AUTOSAR XML (schema 4-2-2)
package /STELLANTIS/EPT/ASWCs
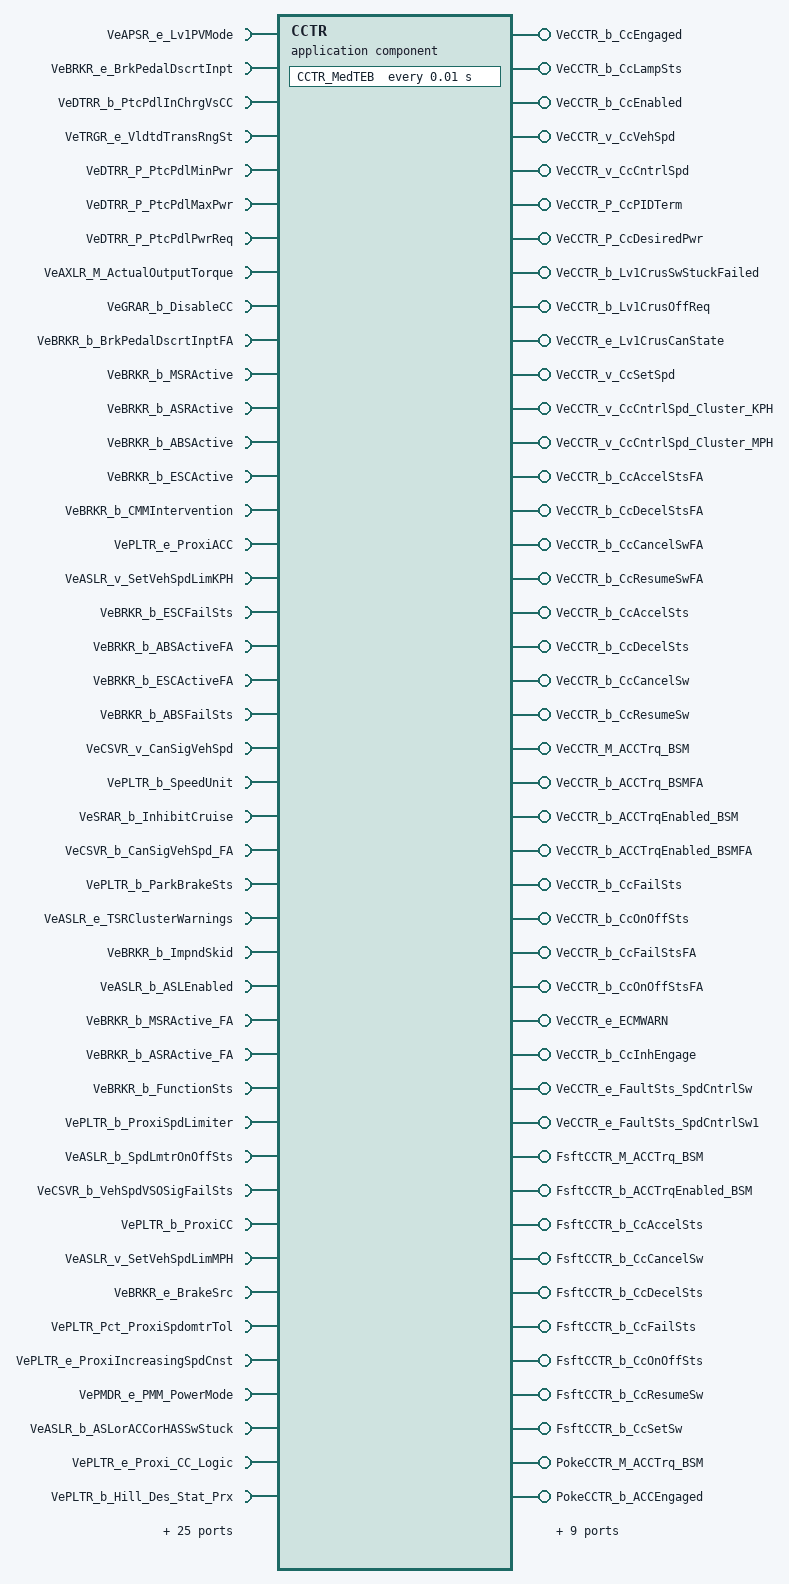
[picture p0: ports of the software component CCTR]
  application sw component type CCTR
    67 x require port:
      VeAPSR_e_Lv1PVMode: variation-point={short-label=vpVeAPSR_e_Lv1PVMode, sw-syscond=1}, nonqueued-receiver-com-spec{data-element=Value, init-value=CeAPSR_e_LV1PVMode_NotValid}, required-interface=VeAPSR_e_Lv1PVMode
      VeBRKR_e_BrkPedalDscrtInpt: variation-point={short-label=vpVeBRKR_e_BrkPedalDscrtInpt, sw-syscond=1}, nonqueued-receiver-com-spec{data-element=Value, init-value=CeBRKR_e_BrkNotApplied}, required-interface=VeBRKR_e_BrkPedalDscrtInpt
      VeDTRR_b_PtcPdlInChrgVsCC: variation-point={short-label=vpVeDTRR_b_PtcPdlInChrgVsCC, sw-syscond=1}, nonqueued-receiver-com-spec{data-element=Value, init-value=0}, required-interface=VeDTRR_b_PtcPdlInChrgVsCC
      VeTRGR_e_VldtdTransRngSt: variation-point={short-label=vpVeTRGR_e_VldtdTransRngSt, sw-syscond=1}, nonqueued-receiver-com-spec{data-element=Value, init-value=CeTRGR_e_NoSelectionAvailable}, required-interface=VeTRGR_e_VldtdTransRngSt
      VeDTRR_P_PtcPdlMinPwr: variation-point={short-label=vpVeDTRR_P_PtcPdlMinPwr, sw-syscond=1}, nonqueued-receiver-com-spec{data-element=Value, init-value=0}, required-interface=VeDTRR_P_PtcPdlMinPwr
      VeDTRR_P_PtcPdlMaxPwr: variation-point={short-label=vpVeDTRR_P_PtcPdlMaxPwr, sw-syscond=1}, nonqueued-receiver-com-spec{data-element=Value, init-value=0}, required-interface=VeDTRR_P_PtcPdlMaxPwr
      VeDTRR_P_PtcPdlPwrReq: variation-point={short-label=vpVeDTRR_P_PtcPdlPwrReq, sw-syscond=1}, nonqueued-receiver-com-spec{data-element=Value, init-value=0}, required-interface=VeDTRR_P_PtcPdlPwrReq
      VeAXLR_M_ActualOutputTorque: variation-point={short-label=vpVeAXLR_M_ActualOutputTorque, sw-syscond=1}, nonqueued-receiver-com-spec{data-element=Value, init-value=0}, required-interface=VeAXLR_M_ActualOutputTorque
      VeGRAR_b_DisableCC: variation-point={short-label=vpVeGRAR_b_DisableCC, sw-syscond=1}, nonqueued-receiver-com-spec{data-element=Value, init-value=0}, required-interface=VeGRAR_b_DisableCC
      VeBRKR_b_BrkPedalDscrtInptFA: variation-point={short-label=vpVeBRKR_b_BrkPedalDscrtInptFA, sw-syscond=1}, nonqueued-receiver-com-spec{data-element=Value, init-value=0}, required-interface=VeBRKR_b_BrkPedalDscrtInptFA
      VeBRKR_b_MSRActive: variation-point={short-label=vpVeBRKR_b_MSRActive, sw-syscond=1}, nonqueued-receiver-com-spec{data-element=Value, init-value=0}, required-interface=VeBRKR_b_MSRActive
      VeBRKR_b_ASRActive: variation-point={short-label=vpVeBRKR_b_ASRActive, sw-syscond=1}, nonqueued-receiver-com-spec{data-element=Value, init-value=0}, required-interface=VeBRKR_b_ASRActive
      VeBRKR_b_ABSActive: variation-point={short-label=vpVeBRKR_b_ABSActive, sw-syscond=1}, nonqueued-receiver-com-spec{data-element=Value, init-value=0}, required-interface=VeBRKR_b_ABSActive
      VeBRKR_b_ESCActive: variation-point={short-label=vpVeBRKR_b_ESCActive, sw-syscond=1}, nonqueued-receiver-com-spec{data-element=Value, init-value=0}, required-interface=VeBRKR_b_ESCActive
      VeBRKR_b_CMMIntervention: variation-point={short-label=vpVeBRKR_b_CMMIntervention, sw-syscond=1}, nonqueued-receiver-com-spec{data-element=Value, init-value=0}, required-interface=VeBRKR_b_CMMIntervention
      VePLTR_e_ProxiACC: variation-point={short-label=vpVePLTR_e_ProxiACC, sw-syscond=1}, nonqueued-receiver-com-spec{data-element=Value, init-value=CePLTR_e_ACC_Absent}, required-interface=VePLTR_e_ProxiACC
      VeASLR_v_SetVehSpdLimKPH: variation-point={short-label=vpVeASLR_v_SetVehSpdLimKPH, sw-syscond=1}, nonqueued-receiver-com-spec{data-element=Value, init-value=0}, required-interface=VeASLR_v_SetVehSpdLimKPH
      VeBRKR_b_ESCFailSts: variation-point={short-label=vpVeBRKR_b_ESCFailSts, sw-syscond=1}, nonqueued-receiver-com-spec{data-element=Value, init-value=0}, required-interface=VeBRKR_b_ESCFailSts
      VeBRKR_b_ABSActiveFA: variation-point={short-label=vpVeBRKR_b_ABSActiveFA, sw-syscond=1}, nonqueued-receiver-com-spec{data-element=Value, init-value=0}, required-interface=VeBRKR_b_ABSActiveFA
      VeBRKR_b_ESCActiveFA: variation-point={short-label=vpVeBRKR_b_ESCActiveFA, sw-syscond=1}, nonqueued-receiver-com-spec{data-element=Value, init-value=0}, required-interface=VeBRKR_b_ESCActiveFA
      VeBRKR_b_ABSFailSts: variation-point={short-label=vpVeBRKR_b_ABSFailSts, sw-syscond=1}, nonqueued-receiver-com-spec{data-element=Value, init-value=0}, required-interface=VeBRKR_b_ABSFailSts
      VeCSVR_v_CanSigVehSpd: variation-point={short-label=vpVeCSVR_v_CanSigVehSpd, sw-syscond=1}, nonqueued-receiver-com-spec{data-element=Value, init-value=0}, required-interface=VeCSVR_v_CanSigVehSpd
      VePLTR_b_SpeedUnit: variation-point={short-label=vpVePLTR_b_SpeedUnit, sw-syscond=1}, nonqueued-receiver-com-spec{data-element=Value, init-value=0}, required-interface=VePLTR_b_SpeedUnit
      VeSRAR_b_InhibitCruise: variation-point={short-label=vpVeSRAR_b_InhibitCruise, sw-syscond=1}, nonqueued-receiver-com-spec{data-element=Value, init-value=0}, required-interface=VeSRAR_b_InhibitCruise
      VeCSVR_b_CanSigVehSpd_FA: variation-point={short-label=vpVeCSVR_b_CanSigVehSpd_FA, sw-syscond=1}, nonqueued-receiver-com-spec{data-element=Value, init-value=0}, required-interface=VeCSVR_b_CanSigVehSpd_FA
      VePLTR_b_ParkBrakeSts: variation-point={short-label=vpVePLTR_b_ParkBrakeSts, sw-syscond=1}, nonqueued-receiver-com-spec{data-element=Value, init-value=0}, required-interface=VePLTR_b_ParkBrakeSts
      VeASLR_e_TSRClusterWarnings: variation-point={short-label=vpVeASLR_e_TSRClusterWarnings, sw-syscond=1}, nonqueued-receiver-com-spec{data-element=Value, init-value=0}, required-interface=VeASLR_e_TSRClusterWarnings
      VeBRKR_b_ImpndSkid: variation-point={short-label=vpVeBRKR_b_ImpndSkid, sw-syscond=1}, nonqueued-receiver-com-spec{data-element=Value, init-value=0}, required-interface=VeBRKR_b_ImpndSkid
      VeASLR_b_ASLEnabled: variation-point={short-label=vpVeASLR_b_ASLEnabled, sw-syscond=1}, nonqueued-receiver-com-spec{data-element=Value, init-value=0}, required-interface=VeASLR_b_ASLEnabled
      VeBRKR_b_MSRActive_FA: variation-point={short-label=vpVeBRKR_b_MSRActive_FA, sw-syscond=1}, nonqueued-receiver-com-spec{data-element=Value, init-value=0}, required-interface=VeBRKR_b_MSRActive_FA
      VeBRKR_b_ASRActive_FA: variation-point={short-label=vpVeBRKR_b_ASRActive_FA, sw-syscond=1}, nonqueued-receiver-com-spec{data-element=Value, init-value=0}, required-interface=VeBRKR_b_ASRActive_FA
      VeBRKR_b_FunctionSts: variation-point={short-label=vpVeBRKR_b_FunctionSts, sw-syscond=1}, nonqueued-receiver-com-spec{data-element=Value, init-value=0}, required-interface=VeBRKR_b_FunctionSts
      VePLTR_b_ProxiSpdLimiter: variation-point={short-label=vpVePLTR_b_ProxiSpdLimiter, sw-syscond=1}, nonqueued-receiver-com-spec{data-element=Value, init-value=0}, required-interface=VePLTR_b_ProxiSpdLimiter
      VeASLR_b_SpdLmtrOnOffSts: variation-point={short-label=vpVeASLR_b_SpdLmtrOnOffSts, sw-syscond=1}, nonqueued-receiver-com-spec{data-element=Value, init-value=0}, required-interface=VeASLR_b_SpdLmtrOnOffSts
      VeCSVR_b_VehSpdVSOSigFailSts: variation-point={short-label=vpVeCSVR_b_VehSpdVSOSigFailSts, sw-syscond=1}, nonqueued-receiver-com-spec{data-element=Value, init-value=0}, required-interface=VeCSVR_b_VehSpdVSOSigFailSts
      VePLTR_b_ProxiCC: variation-point={short-label=vpVePLTR_b_ProxiCC, sw-syscond=1}, nonqueued-receiver-com-spec{data-element=Value, init-value=0}, required-interface=VePLTR_b_ProxiCC
      VeASLR_v_SetVehSpdLimMPH: variation-point={short-label=vpVeASLR_v_SetVehSpdLimMPH, sw-syscond=1}, nonqueued-receiver-com-spec{data-element=Value, init-value=0}, required-interface=VeASLR_v_SetVehSpdLimMPH
      VeBRKR_e_BrakeSrc: variation-point={short-label=vpVeBRKR_e_BrakeSrc, sw-syscond=1}, nonqueued-receiver-com-spec{data-element=Value, init-value=CeBRKR_e_BrkPdlDscrtInpt}, required-interface=VeBRKR_e_BrakeSrc
      VePLTR_Pct_ProxiSpdomtrTol: variation-point={short-label=vpVePLTR_Pct_ProxiSpdomtrTol, sw-syscond=1}, nonqueued-receiver-com-spec{data-element=Value, init-value=0}, required-interface=VePLTR_Pct_ProxiSpdomtrTol
      VePLTR_e_ProxiIncreasingSpdCnst: variation-point={short-label=vpVePLTR_e_ProxiIncreasingSpdCnst, sw-syscond=1}, nonqueued-receiver-com-spec{data-element=Value, init-value=CePLTR_e_Increasing_0}, required-interface=VePLTR_e_ProxiIncreasingSpdCnst
      VePMDR_e_PMM_PowerMode: variation-point={short-label=vpVePMDR_e_PMM_PowerMode, sw-syscond=1}, nonqueued-receiver-com-spec{data-element=Value, init-value=CePMDR_e_PowerMode_Off}, required-interface=VePMDR_e_PMM_PowerMode
      VeASLR_b_ASLorACCorHASSwStuck: variation-point={short-label=vpVeASLR_b_ASLorACCorHASSwStuck, sw-syscond=1}, nonqueued-receiver-com-spec{data-element=Value, init-value=0}, required-interface=VeASLR_b_ASLorACCorHASSwStuck
      VePLTR_e_Proxi_CC_Logic: variation-point={short-label=vpVePLTR_e_Proxi_CC_Logic, sw-syscond=1}, nonqueued-receiver-com-spec{data-element=Value, init-value=CePLTR_e_Logic1}, required-interface=VePLTR_e_Proxi_CC_Logic
      VePLTR_b_Hill_Des_Stat_Prx: variation-point={short-label=vpVePLTR_b_Hill_Des_Stat_Prx, sw-syscond=1}, nonqueued-receiver-com-spec{data-element=Value, init-value=0}, required-interface=VePLTR_b_Hill_Des_Stat_Prx
      VeBRKR_e_ExtTcsReqOff: variation-point={short-label=vpVeBRKR_e_ExtTcsReqOff, sw-syscond=1}, nonqueued-receiver-com-spec{data-element=Value, init-value=CeBRKR_e_NoReq}, required-interface=VeBRKR_e_ExtTcsReqOff
      VeBRKR_e_ExtBrkReqOff: variation-point={short-label=vpVeBRKR_e_ExtBrkReqOff, sw-syscond=1}, nonqueued-receiver-com-spec{data-element=Value, init-value=CeBRKR_e_NoReq}, required-interface=VeBRKR_e_ExtBrkReqOff
      VeASLR_e_HDC_Status: variation-point={short-label=vpVeASLR_e_HDC_Status, sw-syscond=1}, nonqueued-receiver-com-spec{data-element=Value, init-value=CeASLR_e_HDC_UNAVL}, required-interface=VeASLR_e_HDC_Status
      VePLTR_e_EPBHoldSts: variation-point={short-label=vpVePLTR_e_EPBHoldSts, sw-syscond=1}, nonqueued-receiver-com-spec{data-element=Value, init-value=CePLTR_e_EPBHoldSts_REL}, required-interface=VePLTR_e_EPBHoldSts
      VeTMDR_e_TrrnMd: variation-point={short-label=vpVeTMDR_e_TrrnMd, sw-syscond=1}, nonqueued-receiver-com-spec{data-element=Value, init-value=CeTMDR_e_NotDefine}, required-interface=VeTMDR_e_TrrnMd
      VePLTR_b_EPBHoldStsFA: variation-point={short-label=vpVePLTR_b_EPBHoldStsFA, sw-syscond=1}, nonqueued-receiver-com-spec{data-element=Value, init-value=0}, required-interface=VePLTR_b_EPBHoldStsFA
      VeBRKR_b_ExtBrkReqOffFA: variation-point={short-label=vpVeBRKR_b_ExtBrkReqOffFA, sw-syscond=1}, nonqueued-receiver-com-spec{data-element=Value, init-value=0}, required-interface=VeBRKR_b_ExtBrkReqOffFA
      VeBRKR_b_BrkPdlFlt: variation-point={short-label=vpVeBRKR_b_BrkPdlFlt, sw-syscond=1}, nonqueued-receiver-com-spec{data-element=Value, init-value=0}, required-interface=VeBRKR_b_BrkPdlFlt
      VeBRKR_b_BrkPdlFltFA: variation-point={short-label=vpVeBRKR_b_BrkPdlFltFA, sw-syscond=1}, nonqueued-receiver-com-spec{data-element=Value, init-value=0}, required-interface=VeBRKR_b_BrkPdlFltFA
      VeBRKR_b_ESCFailStsFA: variation-point={short-label=vpVeBRKR_b_ESCFailStsFA, sw-syscond=1}, nonqueued-receiver-com-spec{data-element=Value, init-value=0}, required-interface=VeBRKR_b_ESCFailStsFA
      VeAPSR_b_Lv1PvBrkActive: variation-point={short-label=vpVeAPSR_b_Lv1PvBrkActive, sw-syscond=1}, nonqueued-receiver-com-spec{data-element=Value, init-value=0}, required-interface=VeAPSR_b_Lv1PvBrkActive
      VePLTR_v_HomSpdLim: variation-point={short-label=vpVePLTR_v_HomSpdLim, sw-syscond=1}, nonqueued-receiver-com-spec{data-element=Value, init-value=0}, required-interface=VePLTR_v_HomSpdLim
      VeASLR_v_STSpdLim: variation-point={short-label=vpVeASLR_v_STSpdLim, sw-syscond=1}, nonqueued-receiver-com-spec{data-element=Value, init-value=0}, required-interface=VeASLR_v_STSpdLim
      VeASLR_b_STSpdLimEnabled: variation-point={short-label=vpVeASLR_b_STSpdLimEnabled, sw-syscond=1}, nonqueued-receiver-com-spec{data-element=Value, init-value=0}, required-interface=VeASLR_b_STSpdLimEnabled
      VeASLR_b_HomSpdLimEnabled: variation-point={short-label=vpVeASLR_b_HomSpdLimEnabled, sw-syscond=1}, nonqueued-receiver-com-spec{data-element=Value, init-value=0}, required-interface=VeASLR_b_HomSpdLimEnabled
      VePLTR_b_HDCEnabledCAN: variation-point={short-label=vpVePLTR_b_HDCEnabledCAN, sw-syscond=1}, nonqueued-receiver-com-spec{data-element=Value, init-value=0}, required-interface=VePLTR_b_HDCEnabledCAN
      VePLTR_b_HDCEnabledCAN_FA: variation-point={short-label=vpVePLTR_b_HDCEnabledCAN_FA, sw-syscond=1}, nonqueued-receiver-com-spec{data-element=Value, init-value=0}, required-interface=VePLTR_b_HDCEnabledCAN_FA
      VeDFIR_b_DsblDiagFailSafe: variation-point={short-label=vpVeDFIR_b_DsblDiagFailSafe, sw-syscond=1}, nonqueued-receiver-com-spec{data-element=Value, init-value=0}, required-interface=VeDFIR_b_DsblDiagFailSafe
      VeDFIR_b_PostCodeClrDiagDsbl: variation-point={short-label=vpVeDFIR_b_PostCodeClrDiagDsbl, sw-syscond=1}, nonqueued-receiver-com-spec{data-element=Value, init-value=0}, required-interface=VeDFIR_b_PostCodeClrDiagDsbl
      VeDMAB_y_StatusByte_SpdCntrlSw: variation-point={short-label=vpVeDMAB_y_StatusByte_SpdCntrlSw, sw-syscond=1}, nonqueued-receiver-com-spec{data-element=Value, init-value=0}, required-interface=VeDMAB_y_StatusByte_SpdCntrlSw
      VePLTR_e_BSM_AxleTrq_Enbld: variation-point={short-label=vpVePLTR_e_BSM_AxleTrq_Enbld, sw-syscond=1}, nonqueued-receiver-com-spec{data-element=Value, init-value=CePLTR_e_No_Req}, required-interface=VePLTR_e_BSM_AxleTrq_Enbld
      VeDFIR_b_IsDiagGlobalConditionsValid: variation-point={short-label=vpVeDFIR_b_IsDiagGlobalConditionsValid, sw-syscond=1}, nonqueued-receiver-com-spec{data-element=Value, init-value=0}, required-interface=VeDFIR_b_IsDiagGlobalConditionsValid
      VeDMAB_y_StatusByte_SpdCntrlSw1: variation-point={short-label=vpVeDMAB_y_StatusByte_SpdCntrlSw1, sw-syscond=1}, nonqueued-receiver-com-spec{data-element=Value, init-value=0}, required-interface=VeDMAB_y_StatusByte_SpdCntrlSw1
    52 x provide port:
      VeCCTR_b_CcEngaged: variation-point={short-label=vpVeCCTR_b_CcEngaged, sw-syscond=1}, nonqueued-sender-com-spec{data-element=Value, init-value=0}, provided-interface=VeCCTR_b_CcEngaged
      VeCCTR_b_CcLampSts: variation-point={short-label=vpVeCCTR_b_CcLampSts, sw-syscond=1}, nonqueued-sender-com-spec{data-element=Value, init-value=0}, provided-interface=VeCCTR_b_CcLampSts
      VeCCTR_b_CcEnabled: variation-point={short-label=vpVeCCTR_b_CcEnabled, sw-syscond=1}, nonqueued-sender-com-spec{data-element=Value, init-value=0}, provided-interface=VeCCTR_b_CcEnabled
      VeCCTR_v_CcVehSpd: variation-point={short-label=vpVeCCTR_v_CcVehSpd, sw-syscond=1}, nonqueued-sender-com-spec{data-element=Value, init-value=0}, provided-interface=VeCCTR_v_CcVehSpd
      VeCCTR_v_CcCntrlSpd: variation-point={short-label=vpVeCCTR_v_CcCntrlSpd, sw-syscond=1}, nonqueued-sender-com-spec{data-element=Value, init-value=0}, provided-interface=VeCCTR_v_CcCntrlSpd
      VeCCTR_P_CcPIDTerm: variation-point={short-label=vpVeCCTR_P_CcPIDTerm, sw-syscond=1}, nonqueued-sender-com-spec{data-element=Value, init-value=0}, provided-interface=VeCCTR_P_CcPIDTerm
      VeCCTR_P_CcDesiredPwr: variation-point={short-label=vpVeCCTR_P_CcDesiredPwr, sw-syscond=1}, nonqueued-sender-com-spec{data-element=Value, init-value=0}, provided-interface=VeCCTR_P_CcDesiredPwr
      VeCCTR_b_Lv1CrusSwStuckFailed: variation-point={short-label=vpVeCCTR_b_Lv1CrusSwStuckFailed, sw-syscond=1}, nonqueued-sender-com-spec{data-element=Value, init-value=0}, provided-interface=VeCCTR_b_Lv1CrusSwStuckFailed
      VeCCTR_b_Lv1CrusOffReq: variation-point={short-label=vpVeCCTR_b_Lv1CrusOffReq, sw-syscond=1}, nonqueued-sender-com-spec{data-element=Value, init-value=0}, provided-interface=VeCCTR_b_Lv1CrusOffReq
      VeCCTR_e_Lv1CrusCanState: variation-point={short-label=vpVeCCTR_e_Lv1CrusCanState, sw-syscond=1}, nonqueued-sender-com-spec{data-element=Value, init-value=0}, provided-interface=VeCCTR_e_Lv1CrusCanState
      VeCCTR_v_CcSetSpd: variation-point={short-label=vpVeCCTR_v_CcSetSpd, sw-syscond=1}, nonqueued-sender-com-spec{data-element=Value, init-value=0}, provided-interface=VeCCTR_v_CcSetSpd
      VeCCTR_v_CcCntrlSpd_Cluster_KPH: variation-point={short-label=vpVeCCTR_v_CcCntrlSpd_Cluster_KPH, sw-syscond=1}, nonqueued-sender-com-spec{data-element=Value, init-value=0}, provided-interface=VeCCTR_v_CcCntrlSpd_Cluster_KPH
      VeCCTR_v_CcCntrlSpd_Cluster_MPH: variation-point={short-label=vpVeCCTR_v_CcCntrlSpd_Cluster_MPH, sw-syscond=1}, nonqueued-sender-com-spec{data-element=Value, init-value=0}, provided-interface=VeCCTR_v_CcCntrlSpd_Cluster_MPH
      VeCCTR_b_CcAccelStsFA: nonqueued-sender-com-spec{data-element=Value, init-value=0}, provided-interface=VeCCTR_b_CcAccelStsFA
      VeCCTR_b_CcDecelStsFA: nonqueued-sender-com-spec{data-element=Value, init-value=0}, provided-interface=VeCCTR_b_CcDecelStsFA
      VeCCTR_b_CcCancelSwFA: nonqueued-sender-com-spec{data-element=Value, init-value=0}, provided-interface=VeCCTR_b_CcCancelSwFA
      VeCCTR_b_CcResumeSwFA: nonqueued-sender-com-spec{data-element=Value, init-value=0}, provided-interface=VeCCTR_b_CcResumeSwFA
      VeCCTR_b_CcAccelSts: variation-point={short-label=vpVeCCTR_b_CcAccelSts, sw-syscond=1}, nonqueued-sender-com-spec{data-element=Value, init-value=0}, provided-interface=VeCCTR_b_CcAccelSts
      VeCCTR_b_CcDecelSts: variation-point={short-label=vpVeCCTR_b_CcDecelSts, sw-syscond=1}, nonqueued-sender-com-spec{data-element=Value, init-value=0}, provided-interface=VeCCTR_b_CcDecelSts
      VeCCTR_b_CcCancelSw: variation-point={short-label=vpVeCCTR_b_CcCancelSw, sw-syscond=1}, nonqueued-sender-com-spec{data-element=Value, init-value=0}, provided-interface=VeCCTR_b_CcCancelSw
      VeCCTR_b_CcResumeSw: variation-point={short-label=vpVeCCTR_b_CcResumeSw, sw-syscond=1}, nonqueued-sender-com-spec{data-element=Value, init-value=0}, provided-interface=VeCCTR_b_CcResumeSw
      VeCCTR_M_ACCTrq_BSM: nonqueued-sender-com-spec{data-element=Value, init-value=0}, provided-interface=VeCCTR_M_ACCTrq_BSM
      VeCCTR_b_ACCTrq_BSMFA: nonqueued-sender-com-spec{data-element=Value, init-value=0}, provided-interface=VeCCTR_b_ACCTrq_BSMFA
      VeCCTR_b_ACCTrqEnabled_BSM: variation-point={short-label=vpVeCCTR_b_ACCTrqEnabled_BSM, sw-syscond=1}, nonqueued-sender-com-spec{data-element=Value, init-value=0}, provided-interface=VeCCTR_b_ACCTrqEnabled_BSM
      VeCCTR_b_ACCTrqEnabled_BSMFA: variation-point={short-label=vpVeCCTR_b_ACCTrqEnabled_BSMFA, sw-syscond=1}, nonqueued-sender-com-spec{data-element=Value, init-value=0}, provided-interface=VeCCTR_b_ACCTrqEnabled_BSMFA
      VeCCTR_b_CcFailSts: nonqueued-sender-com-spec{data-element=Value, init-value=0}, provided-interface=VeCCTR_b_CcFailSts
      VeCCTR_b_CcOnOffSts: nonqueued-sender-com-spec{data-element=Value, init-value=0}, provided-interface=VeCCTR_b_CcOnOffSts
      VeCCTR_b_CcFailStsFA: nonqueued-sender-com-spec{data-element=Value, init-value=0}, provided-interface=VeCCTR_b_CcFailStsFA
      VeCCTR_b_CcOnOffStsFA: nonqueued-sender-com-spec{data-element=Value, init-value=0}, provided-interface=VeCCTR_b_CcOnOffStsFA
      VeCCTR_e_ECMWARN: variation-point={short-label=vpVeCCTR_e_ECMWARN, sw-syscond=1}, nonqueued-sender-com-spec{data-element=Value, init-value=0}, provided-interface=VeCCTR_e_ECMWARN
      VeCCTR_b_CcInhEngage: variation-point={short-label=vpVeCCTR_b_CcInhEngage, sw-syscond=1}, nonqueued-sender-com-spec{data-element=Value, init-value=0}, provided-interface=VeCCTR_b_CcInhEngage
      VeCCTR_e_FaultSts_SpdCntrlSw: nonqueued-sender-com-spec{data-element=Value, init-value=CeDFIB_e_Init}, provided-interface=VeCCTR_e_FaultSts_SpdCntrlSw
      VeCCTR_e_FaultSts_SpdCntrlSw1: nonqueued-sender-com-spec{data-element=Value, init-value=CeDFIB_e_Init}, provided-interface=VeCCTR_e_FaultSts_SpdCntrlSw1
      FsftCCTR_M_ACCTrq_BSM: server-com-spec=FsftCCTR_M_ACCTrq_BSM, provided-interface=FsftCCTR_M_ACCTrq_BSM
      FsftCCTR_b_ACCTrqEnabled_BSM: server-com-spec=FsftCCTR_b_ACCTrqEnabled_BSM, provided-interface=FsftCCTR_b_ACCTrqEnabled_BSM
      FsftCCTR_b_CcAccelSts: server-com-spec=FsftCCTR_b_CcAccelSts, provided-interface=FsftCCTR_b_CcAccelSts
      FsftCCTR_b_CcCancelSw: server-com-spec=FsftCCTR_b_CcCancelSw, provided-interface=FsftCCTR_b_CcCancelSw
      FsftCCTR_b_CcDecelSts: server-com-spec=FsftCCTR_b_CcDecelSts, provided-interface=FsftCCTR_b_CcDecelSts
      FsftCCTR_b_CcFailSts: server-com-spec=FsftCCTR_b_CcFailSts, provided-interface=FsftCCTR_b_CcFailSts
      FsftCCTR_b_CcOnOffSts: server-com-spec=FsftCCTR_b_CcOnOffSts, provided-interface=FsftCCTR_b_CcOnOffSts
      FsftCCTR_b_CcResumeSw: server-com-spec=FsftCCTR_b_CcResumeSw, provided-interface=FsftCCTR_b_CcResumeSw
      FsftCCTR_b_CcSetSw: server-com-spec=FsftCCTR_b_CcSetSw, provided-interface=FsftCCTR_b_CcSetSw
      PokeCCTR_M_ACCTrq_BSM: server-com-spec{operation=PokeCCTR_M_ACCTrq_BSM, queue-length=1}, provided-interface=PokeCCTR_M_ACCTrq_BSM
      PokeCCTR_b_ACCEngaged: server-com-spec{operation=PokeCCTR_b_ACCEngaged, queue-length=1}, provided-interface=PokeCCTR_b_ACCEngaged
      PokeCCTR_b_ACCTrqEnabled_BSM: server-com-spec{operation=PokeCCTR_b_ACCTrqEnabled_BSM, queue-length=1}, provided-interface=PokeCCTR_b_ACCTrqEnabled_BSM
      PokeCCTR_b_CcAccelSts: server-com-spec{operation=PokeCCTR_b_CcAccelSts, queue-length=1}, provided-interface=PokeCCTR_b_CcAccelSts
      PokeCCTR_b_CcCancelSw: server-com-spec{operation=PokeCCTR_b_CcCancelSw, queue-length=1}, provided-interface=PokeCCTR_b_CcCancelSw
      PokeCCTR_b_CcDecelSts: server-com-spec{operation=PokeCCTR_b_CcDecelSts, queue-length=1}, provided-interface=PokeCCTR_b_CcDecelSts
      PokeCCTR_b_CcFailSts: server-com-spec{operation=PokeCCTR_b_CcFailSts, queue-length=1}, provided-interface=PokeCCTR_b_CcFailSts
      PokeCCTR_b_CcOnOffSts: server-com-spec{operation=PokeCCTR_b_CcOnOffSts, queue-length=1}, provided-interface=PokeCCTR_b_CcOnOffSts
      PokeCCTR_b_CcResumeSw: server-com-spec{operation=PokeCCTR_b_CcResumeSw, queue-length=1}, provided-interface=PokeCCTR_b_CcResumeSw
      PokeCCTR_b_CcSetSw: server-com-spec{operation=PokeCCTR_b_CcSetSw, queue-length=1}, provided-interface=PokeCCTR_b_CcSetSw
    require port NeCCTR_Cnt_SpdCntrlSw1_MFOP_Rx: nv-require-com-spec{init-value=0, variable=NeCCTR_Cnt_SpdCntrlSw1_MFOP}, required-interface=NeCCTR_Cnt_SpdCntrlSw1_MFOP
    provide port NeCCTR_Cnt_SpdCntrlSw1_MFOP: nv-provide-com-spec{ram-block-init-value=0, variable=NeCCTR_Cnt_SpdCntrlSw1_MFOP}, provided-interface=NeCCTR_Cnt_SpdCntrlSw1_MFOP
    require port KeASLR_b_ASLInstantActivationEnable: parameter-require-com-spec{init-value=KeASLR_b_ASLInstantActivationEnable_KeASLR_b_ASLInstantActivationEnable:1, parameter=KeASLR_b_ASLInstantActivationEnable}, required-interface=KeASLR_b_ASLInstantActivationEnable
    behavior IB_CCTR: data-type-mapping=msADTtoIDTMapping, handle-termination-and-restart=NO-SUPPORT
      timing event Event_MedTEB: start-on-event=CCTR_MedTEB, period=0.01
      19 x operation invoked event:
        Event_FsftCCTR_M_ACCTrq_BSM: start-on-event=FsftCCTR_M_ACCTrq_BSM, operation=FsftCCTR_M_ACCTrq_BSM.FsftCCTR_M_ACCTrq_BSM
        Event_FsftCCTR_b_ACCTrqEnabled_BSM: start-on-event=FsftCCTR_b_ACCTrqEnabled_BSM, operation=FsftCCTR_b_ACCTrqEnabled_BSM.FsftCCTR_b_ACCTrqEnabled_BSM
        Event_FsftCCTR_b_CcAccelSts: start-on-event=FsftCCTR_b_CcAccelSts, operation=FsftCCTR_b_CcAccelSts.FsftCCTR_b_CcAccelSts
        Event_FsftCCTR_b_CcCancelSw: start-on-event=FsftCCTR_b_CcCancelSw, operation=FsftCCTR_b_CcCancelSw.FsftCCTR_b_CcCancelSw
        Event_FsftCCTR_b_CcDecelSts: start-on-event=FsftCCTR_b_CcDecelSts, operation=FsftCCTR_b_CcDecelSts.FsftCCTR_b_CcDecelSts
        Event_FsftCCTR_b_CcFailSts: start-on-event=FsftCCTR_b_CcFailSts, operation=FsftCCTR_b_CcFailSts.FsftCCTR_b_CcFailSts
        Event_FsftCCTR_b_CcOnOffSts: start-on-event=FsftCCTR_b_CcOnOffSts, operation=FsftCCTR_b_CcOnOffSts.FsftCCTR_b_CcOnOffSts
        Event_FsftCCTR_b_CcResumeSw: start-on-event=FsftCCTR_b_CcResumeSw, operation=FsftCCTR_b_CcResumeSw.FsftCCTR_b_CcResumeSw
        Event_FsftCCTR_b_CcSetSw: start-on-event=FsftCCTR_b_CcSetSw, operation=FsftCCTR_b_CcSetSw.FsftCCTR_b_CcSetSw
        Event_PokeCCTR_M_ACCTrq_BSM: start-on-event=PokeCCTR_M_ACCTrq_BSM, operation=PokeCCTR_M_ACCTrq_BSM.PokeCCTR_M_ACCTrq_BSM
        Event_PokeCCTR_b_ACCEngaged: start-on-event=PokeCCTR_b_ACCEngaged, operation=PokeCCTR_b_ACCEngaged.PokeCCTR_b_ACCEngaged
        Event_PokeCCTR_b_ACCTrqEnabled_BSM: start-on-event=PokeCCTR_b_ACCTrqEnabled_BSM, operation=PokeCCTR_b_ACCTrqEnabled_BSM.PokeCCTR_b_ACCTrqEnabled_BSM
        Event_PokeCCTR_b_CcAccelSts: start-on-event=PokeCCTR_b_CcAccelSts, operation=PokeCCTR_b_CcAccelSts.PokeCCTR_b_CcAccelSts
        Event_PokeCCTR_b_CcCancelSw: start-on-event=PokeCCTR_b_CcCancelSw, operation=PokeCCTR_b_CcCancelSw.PokeCCTR_b_CcCancelSw
        Event_PokeCCTR_b_CcDecelSts: start-on-event=PokeCCTR_b_CcDecelSts, operation=PokeCCTR_b_CcDecelSts.PokeCCTR_b_CcDecelSts
        Event_PokeCCTR_b_CcFailSts: start-on-event=PokeCCTR_b_CcFailSts, operation=PokeCCTR_b_CcFailSts.PokeCCTR_b_CcFailSts
        Event_PokeCCTR_b_CcOnOffSts: start-on-event=PokeCCTR_b_CcOnOffSts, operation=PokeCCTR_b_CcOnOffSts.PokeCCTR_b_CcOnOffSts
        Event_PokeCCTR_b_CcResumeSw: start-on-event=PokeCCTR_b_CcResumeSw, operation=PokeCCTR_b_CcResumeSw.PokeCCTR_b_CcResumeSw
        Event_PokeCCTR_b_CcSetSw: start-on-event=PokeCCTR_b_CcSetSw, operation=PokeCCTR_b_CcSetSw.PokeCCTR_b_CcSetSw
      init event Event_CCTR_ac_Init: start-on-event=CCTR_ac_Init
      init event Event_PwrOn: start-on-event=CCTR_PwrOn
      init event Event_PwrOff: start-on-event=CCTR_PwrOff
      explicit-inter-runnable-variables:
        16 x data, all with category=VALUE, sw-calibration-access=READ-ONLY, type=Boolean, init-value=0:
          CC_Accel_Sts_write_IRV: variation-point={short-label=vpCC_Accel_Sts_write_IRV, sw-syscond=1}
          CC_CoastDecelSts_write_IRV: variation-point={short-label=vpCC_CoastDecelSts_write_IRV, sw-syscond=1}
          CC_Cancel_Swtch_write_IRV: variation-point={short-label=vpCC_Cancel_Swtch_write_IRV, sw-syscond=1}
          CC_ResumeSwtch_write_IRV: variation-point={short-label=vpCC_ResumeSwtch_write_IRV, sw-syscond=1}
          CC_OnOff_Sts_write_IRV
          CC_SetSwtch_write_IRV: variation-point={short-label=vpCC_SetSwtch_write_IRV, sw-syscond=1}
          CC_AccelStsFA_write_IRV
          CC_CoastDecelStsFA_write_IRV
          CC_CancelSwtchFA_write_IRV
          CC_ResumeSwtchFA_write_IRV
          CC_FailSts_write_IRV
          CC_OnOffStsFA_write_IRV
          CC_SetSwtchFA_write_IRV
          CC_FailStsFA_write_IRV
          ACC_TrqEnabled_BSM_IRV
          ACC_TrqEnabled_BSMFA_IRV
      23 x runnable:
        CCTR_ac_Init
          data-send-points:
            access OUT_VeCCTR_e_FaultSts_SpdCntrlSw_Value: accessed-variable=VeCCTR_e_FaultSts_SpdCntrlSw.Value
            access OUT_VeCCTR_e_FaultSts_SpdCntrlSw1_Value: accessed-variable=VeCCTR_e_FaultSts_SpdCntrlSw1.Value
        CCTR_PwrOn
          data-receive-point-by-arguments:
            access IN_NeCCTR_Cnt_SpdCntrlSw1_MFOP_Rx_NeCCTR_Cnt_SpdCntrlSw1_MFOP: accessed-variable=NeCCTR_Cnt_SpdCntrlSw1_MFOP_Rx.NeCCTR_Cnt_SpdCntrlSw1_MFOP
          data-send-points:
            33 x access:
              OUT_VeCCTR_M_ACCTrq_BSM_Value: accessed-variable=VeCCTR_M_ACCTrq_BSM.Value
              OUT_VeCCTR_b_CcOnOffStsFA_Value: accessed-variable=VeCCTR_b_CcOnOffStsFA.Value
              OUT_VeCCTR_b_CcDecelStsFA_Value: accessed-variable=VeCCTR_b_CcDecelStsFA.Value
              OUT_VeCCTR_b_CcResumeSwFA_Value: accessed-variable=VeCCTR_b_CcResumeSwFA.Value
              OUT_VeCCTR_b_CcFailStsFA_Value: accessed-variable=VeCCTR_b_CcFailStsFA.Value
              OUT_VeCCTR_b_ACCTrq_BSMFA_Value: accessed-variable=VeCCTR_b_ACCTrq_BSMFA.Value
              OUT_VeCCTR_b_CcOnOffSts_Value: accessed-variable=VeCCTR_b_CcOnOffSts.Value
              OUT_VeCCTR_b_CcFailSts_Value: accessed-variable=VeCCTR_b_CcFailSts.Value
              OUT_VeCCTR_b_CcAccelStsFA_Value: accessed-variable=VeCCTR_b_CcAccelStsFA.Value
              OUT_VeCCTR_b_CcCancelSwFA_Value: accessed-variable=VeCCTR_b_CcCancelSwFA.Value
              OUT_VeCCTR_b_CcEngaged_Value: accessed-variable=VeCCTR_b_CcEngaged.Value, variation-point={short-label=vpOUT_VeCCTR_b_CcEngaged_Value, sw-syscond=1}
              OUT_VeCCTR_b_CcLampSts_Value: accessed-variable=VeCCTR_b_CcLampSts.Value, variation-point={short-label=vpOUT_VeCCTR_b_CcLampSts_Value, sw-syscond=1}
              OUT_VeCCTR_v_CcSetSpd_Value: accessed-variable=VeCCTR_v_CcSetSpd.Value, variation-point={short-label=vpOUT_VeCCTR_v_CcSetSpd_Value, sw-syscond=1}
              OUT_VeCCTR_v_CcCntrlSpd_Cluster_KPH_Value: accessed-variable=VeCCTR_v_CcCntrlSpd_Cluster_KPH.Value, variation-point={short-label=vpOUT_VeCCTR_v_CcCntrlSpd_Cluster_KPH_Value, sw-syscond=1}
              OUT_VeCCTR_v_CcCntrlSpd_Cluster_MPH_Value: accessed-variable=VeCCTR_v_CcCntrlSpd_Cluster_MPH.Value, variation-point={short-label=vpOUT_VeCCTR_v_CcCntrlSpd_Cluster_MPH_Value, sw-syscond=1}
              OUT_VeCCTR_b_CcAccelSts_Value: accessed-variable=VeCCTR_b_CcAccelSts.Value, variation-point={short-label=vpOUT_VeCCTR_b_CcAccelSts_Value, sw-syscond=1}
              OUT_VeCCTR_b_CcDecelSts_Value: accessed-variable=VeCCTR_b_CcDecelSts.Value, variation-point={short-label=vpOUT_VeCCTR_b_CcDecelSts_Value, sw-syscond=1}
              OUT_VeCCTR_b_CcCancelSw_Value: accessed-variable=VeCCTR_b_CcCancelSw.Value, variation-point={short-label=vpOUT_VeCCTR_b_CcCancelSw_Value, sw-syscond=1}
              OUT_VeCCTR_b_CcEnabled_Value: accessed-variable=VeCCTR_b_CcEnabled.Value, variation-point={short-label=vpOUT_VeCCTR_b_CcEnabled_Value, sw-syscond=1}
              OUT_VeCCTR_b_CcResumeSw_Value: accessed-variable=VeCCTR_b_CcResumeSw.Value, variation-point={short-label=vpOUT_VeCCTR_b_CcResumeSw_Value, sw-syscond=1}
              OUT_VeCCTR_e_ECMWARN_Value: accessed-variable=VeCCTR_e_ECMWARN.Value, variation-point={short-label=vpOUT_VeCCTR_e_ECMWARN_Value, sw-syscond=1}
              OUT_VeCCTR_v_CcVehSpd_Value: accessed-variable=VeCCTR_v_CcVehSpd.Value, variation-point={short-label=vpOUT_VeCCTR_v_CcVehSpd_Value, sw-syscond=1}
              OUT_VeCCTR_b_CcInhEngage_Value: accessed-variable=VeCCTR_b_CcInhEngage.Value, variation-point={short-label=vpOUT_VeCCTR_b_CcInhEngage_Value, sw-syscond=1}
              OUT_VeCCTR_v_CcCntrlSpd_Value: accessed-variable=VeCCTR_v_CcCntrlSpd.Value, variation-point={short-label=vpOUT_VeCCTR_v_CcCntrlSpd_Value, sw-syscond=1}
              OUT_VeCCTR_P_CcPIDTerm_Value: accessed-variable=VeCCTR_P_CcPIDTerm.Value, variation-point={short-label=vpOUT_VeCCTR_P_CcPIDTerm_Value, sw-syscond=1}
              OUT_VeCCTR_P_CcDesiredPwr_Value: accessed-variable=VeCCTR_P_CcDesiredPwr.Value, variation-point={short-label=vpOUT_VeCCTR_P_CcDesiredPwr_Value, sw-syscond=1}
              OUT_VeCCTR_b_Lv1CrusSwStuckFailed_Value: accessed-variable=VeCCTR_b_Lv1CrusSwStuckFailed.Value, variation-point={short-label=vpOUT_VeCCTR_b_Lv1CrusSwStuckFailed_Value, sw-syscond=1}
              OUT_VeCCTR_b_Lv1CrusOffReq_Value: accessed-variable=VeCCTR_b_Lv1CrusOffReq.Value, variation-point={short-label=vpOUT_VeCCTR_b_Lv1CrusOffReq_Value, sw-syscond=1}
              OUT_VeCCTR_e_Lv1CrusCanState_Value: accessed-variable=VeCCTR_e_Lv1CrusCanState.Value, variation-point={short-label=vpOUT_VeCCTR_e_Lv1CrusCanState_Value, sw-syscond=1}
              OUT_VeCCTR_e_FaultSts_SpdCntrlSw_Value: accessed-variable=VeCCTR_e_FaultSts_SpdCntrlSw.Value
              OUT_VeCCTR_b_ACCTrqEnabled_BSM_Value: accessed-variable=VeCCTR_b_ACCTrqEnabled_BSM.Value, variation-point={short-label=vpOUT_VeCCTR_b_ACCTrqEnabled_BSM_Value, sw-syscond=1}
              OUT_VeCCTR_b_ACCTrqEnabled_BSMFA_Value: accessed-variable=VeCCTR_b_ACCTrqEnabled_BSMFA.Value, variation-point={short-label=vpOUT_VeCCTR_b_ACCTrqEnabled_BSMFA_Value, sw-syscond=1}
              OUT_VeCCTR_e_FaultSts_SpdCntrlSw1_Value: accessed-variable=VeCCTR_e_FaultSts_SpdCntrlSw1.Value
          written-local-variables:
            16 x access:
              WV_ACC_TrqEnabled_BSMFA_IRV: accessed-variable=ACC_TrqEnabled_BSMFA_IRV
              WV_ACC_TrqEnabled_BSM_IRV: accessed-variable=ACC_TrqEnabled_BSM_IRV
              WV_CC_AccelStsFA_write_IRV: accessed-variable=CC_AccelStsFA_write_IRV
              WV_CC_Accel_Sts_write_IRV: accessed-variable=CC_Accel_Sts_write_IRV, variation-point={short-label=vpWV_CC_Accel_Sts_write_IRV, sw-syscond=1}
              WV_CC_CancelSwtchFA_write_IRV: accessed-variable=CC_CancelSwtchFA_write_IRV
              WV_CC_Cancel_Swtch_write_IRV: accessed-variable=CC_Cancel_Swtch_write_IRV, variation-point={short-label=vpWV_CC_Cancel_Swtch_write_IRV, sw-syscond=1}
              WV_CC_CoastDecelStsFA_write_IRV: accessed-variable=CC_CoastDecelStsFA_write_IRV
              WV_CC_CoastDecelSts_write_IRV: accessed-variable=CC_CoastDecelSts_write_IRV, variation-point={short-label=vpWV_CC_CoastDecelSts_write_IRV, sw-syscond=1}
              WV_CC_FailStsFA_write_IRV: accessed-variable=CC_FailStsFA_write_IRV
              WV_CC_FailSts_write_IRV: accessed-variable=CC_FailSts_write_IRV
              WV_CC_OnOffStsFA_write_IRV: accessed-variable=CC_OnOffStsFA_write_IRV
              WV_CC_OnOff_Sts_write_IRV: accessed-variable=CC_OnOff_Sts_write_IRV
              WV_CC_ResumeSwtchFA_write_IRV: accessed-variable=CC_ResumeSwtchFA_write_IRV
              WV_CC_ResumeSwtch_write_IRV: accessed-variable=CC_ResumeSwtch_write_IRV, variation-point={short-label=vpWV_CC_ResumeSwtch_write_IRV, sw-syscond=1}
              WV_CC_SetSwtchFA_write_IRV: accessed-variable=CC_SetSwtchFA_write_IRV
              WV_CC_SetSwtch_write_IRV: accessed-variable=CC_SetSwtch_write_IRV, variation-point={short-label=vpWV_CC_SetSwtch_write_IRV, sw-syscond=1}
        CCTR_MedTEB: variation-point={short-label=vpCCTR_MedTEB, sw-syscond=1}
          data-receive-point-by-arguments:
            67 x access:
              IN_VeAPSR_b_Lv1PvBrkActive_Value: accessed-variable=VeAPSR_b_Lv1PvBrkActive.Value, variation-point={short-label=vpIN_VeAPSR_b_Lv1PvBrkActive_Value, sw-syscond=1}
              IN_VeAPSR_e_Lv1PVMode_Value: accessed-variable=VeAPSR_e_Lv1PVMode.Value, variation-point={short-label=vpIN_VeAPSR_e_Lv1PVMode_Value, sw-syscond=1}
              IN_VeASLR_b_ASLEnabled_Value: accessed-variable=VeASLR_b_ASLEnabled.Value, variation-point={short-label=vpIN_VeASLR_b_ASLEnabled_Value, sw-syscond=1}
              IN_VeASLR_b_ASLorACCorHASSwStuck_Value: accessed-variable=VeASLR_b_ASLorACCorHASSwStuck.Value, variation-point={short-label=vpIN_VeASLR_b_ASLorACCorHASSwStuck_Value, sw-syscond=1}
              IN_VeASLR_b_HomSpdLimEnabled_Value: accessed-variable=VeASLR_b_HomSpdLimEnabled.Value, variation-point={short-label=vpIN_VeASLR_b_HomSpdLimEnabled_Value, sw-syscond=1}
              IN_VeASLR_b_STSpdLimEnabled_Value: accessed-variable=VeASLR_b_STSpdLimEnabled.Value, variation-point={short-label=vpIN_VeASLR_b_STSpdLimEnabled_Value, sw-syscond=1}
              IN_VeASLR_b_SpdLmtrOnOffSts_Value: accessed-variable=VeASLR_b_SpdLmtrOnOffSts.Value, variation-point={short-label=vpIN_VeASLR_b_SpdLmtrOnOffSts_Value, sw-syscond=1}
              IN_VeASLR_e_HDC_Status_Value: accessed-variable=VeASLR_e_HDC_Status.Value, variation-point={short-label=vpIN_VeASLR_e_HDC_Status_Value, sw-syscond=1}
              IN_VeASLR_e_TSRClusterWarnings_Value: accessed-variable=VeASLR_e_TSRClusterWarnings.Value, variation-point={short-label=vpIN_VeASLR_e_TSRClusterWarnings_Value, sw-syscond=1}
              IN_VeASLR_v_STSpdLim_Value: accessed-variable=VeASLR_v_STSpdLim.Value, variation-point={short-label=vpIN_VeASLR_v_STSpdLim_Value, sw-syscond=1}
              IN_VeASLR_v_SetVehSpdLimKPH_Value: accessed-variable=VeASLR_v_SetVehSpdLimKPH.Value, variation-point={short-label=vpIN_VeASLR_v_SetVehSpdLimKPH_Value, sw-syscond=1}
              IN_VeASLR_v_SetVehSpdLimMPH_Value: accessed-variable=VeASLR_v_SetVehSpdLimMPH.Value, variation-point={short-label=vpIN_VeASLR_v_SetVehSpdLimMPH_Value, sw-syscond=1}
              IN_VeAXLR_M_ActualOutputTorque_Value: accessed-variable=VeAXLR_M_ActualOutputTorque.Value, variation-point={short-label=vpIN_VeAXLR_M_ActualOutputTorque_Value, sw-syscond=1}
              IN_VeBRKR_b_ABSActive_Value: accessed-variable=VeBRKR_b_ABSActive.Value, variation-point={short-label=vpIN_VeBRKR_b_ABSActive_Value, sw-syscond=1}
              IN_VeBRKR_b_ABSActiveFA_Value: accessed-variable=VeBRKR_b_ABSActiveFA.Value, variation-point={short-label=vpIN_VeBRKR_b_ABSActiveFA_Value, sw-syscond=1}
              IN_VeBRKR_b_ABSFailSts_Value: accessed-variable=VeBRKR_b_ABSFailSts.Value, variation-point={short-label=vpIN_VeBRKR_b_ABSFailSts_Value, sw-syscond=1}
              IN_VeBRKR_b_ASRActive_Value: accessed-variable=VeBRKR_b_ASRActive.Value, variation-point={short-label=vpIN_VeBRKR_b_ASRActive_Value, sw-syscond=1}
              IN_VeBRKR_b_ASRActive_FA_Value: accessed-variable=VeBRKR_b_ASRActive_FA.Value, variation-point={short-label=vpIN_VeBRKR_b_ASRActive_FA_Value, sw-syscond=1}
              IN_VeBRKR_b_BrkPdlFlt_Value: accessed-variable=VeBRKR_b_BrkPdlFlt.Value, variation-point={short-label=vpIN_VeBRKR_b_BrkPdlFlt_Value, sw-syscond=1}
              IN_VeBRKR_b_BrkPdlFltFA_Value: accessed-variable=VeBRKR_b_BrkPdlFltFA.Value, variation-point={short-label=vpIN_VeBRKR_b_BrkPdlFltFA_Value, sw-syscond=1}
              IN_VeBRKR_b_BrkPedalDscrtInptFA_Value: accessed-variable=VeBRKR_b_BrkPedalDscrtInptFA.Value, variation-point={short-label=vpIN_VeBRKR_b_BrkPedalDscrtInptFA_Value, sw-syscond=1}
              IN_VeBRKR_b_CMMIntervention_Value: accessed-variable=VeBRKR_b_CMMIntervention.Value, variation-point={short-label=vpIN_VeBRKR_b_CMMIntervention_Value, sw-syscond=1}
              IN_VeBRKR_b_ESCActive_Value: accessed-variable=VeBRKR_b_ESCActive.Value, variation-point={short-label=vpIN_VeBRKR_b_ESCActive_Value, sw-syscond=1}
              IN_VeBRKR_b_ESCActiveFA_Value: accessed-variable=VeBRKR_b_ESCActiveFA.Value, variation-point={short-label=vpIN_VeBRKR_b_ESCActiveFA_Value, sw-syscond=1}
              IN_VeBRKR_b_ESCFailSts_Value: accessed-variable=VeBRKR_b_ESCFailSts.Value, variation-point={short-label=vpIN_VeBRKR_b_ESCFailSts_Value, sw-syscond=1}
              IN_VeBRKR_b_ESCFailStsFA_Value: accessed-variable=VeBRKR_b_ESCFailStsFA.Value, variation-point={short-label=vpIN_VeBRKR_b_ESCFailStsFA_Value, sw-syscond=1}
              IN_VeBRKR_b_ExtBrkReqOffFA_Value: accessed-variable=VeBRKR_b_ExtBrkReqOffFA.Value, variation-point={short-label=vpIN_VeBRKR_b_ExtBrkReqOffFA_Value, sw-syscond=1}
              IN_VeBRKR_b_FunctionSts_Value: accessed-variable=VeBRKR_b_FunctionSts.Value, variation-point={short-label=vpIN_VeBRKR_b_FunctionSts_Value, sw-syscond=1}
              IN_VeBRKR_b_ImpndSkid_Value: accessed-variable=VeBRKR_b_ImpndSkid.Value, variation-point={short-label=vpIN_VeBRKR_b_ImpndSkid_Value, sw-syscond=1}
              IN_VeBRKR_b_MSRActive_Value: accessed-variable=VeBRKR_b_MSRActive.Value, variation-point={short-label=vpIN_VeBRKR_b_MSRActive_Value, sw-syscond=1}
              IN_VeBRKR_b_MSRActive_FA_Value: accessed-variable=VeBRKR_b_MSRActive_FA.Value, variation-point={short-label=vpIN_VeBRKR_b_MSRActive_FA_Value, sw-syscond=1}
              IN_VeBRKR_e_BrakeSrc_Value: accessed-variable=VeBRKR_e_BrakeSrc.Value, variation-point={short-label=vpIN_VeBRKR_e_BrakeSrc_Value, sw-syscond=1}
              IN_VeBRKR_e_BrkPedalDscrtInpt_Value: accessed-variable=VeBRKR_e_BrkPedalDscrtInpt.Value, variation-point={short-label=vpIN_VeBRKR_e_BrkPedalDscrtInpt_Value, sw-syscond=1}
              IN_VeBRKR_e_ExtBrkReqOff_Value: accessed-variable=VeBRKR_e_ExtBrkReqOff.Value, variation-point={short-label=vpIN_VeBRKR_e_ExtBrkReqOff_Value, sw-syscond=1}
              IN_VeBRKR_e_ExtTcsReqOff_Value: accessed-variable=VeBRKR_e_ExtTcsReqOff.Value, variation-point={short-label=vpIN_VeBRKR_e_ExtTcsReqOff_Value, sw-syscond=1}
              IN_VeCSVR_b_CanSigVehSpd_FA_Value: accessed-variable=VeCSVR_b_CanSigVehSpd_FA.Value, variation-point={short-label=vpIN_VeCSVR_b_CanSigVehSpd_FA_Value, sw-syscond=1}
              IN_VeCSVR_b_VehSpdVSOSigFailSts_Value: accessed-variable=VeCSVR_b_VehSpdVSOSigFailSts.Value, variation-point={short-label=vpIN_VeCSVR_b_VehSpdVSOSigFailSts_Value, sw-syscond=1}
              IN_VeCSVR_v_CanSigVehSpd_Value: accessed-variable=VeCSVR_v_CanSigVehSpd.Value, variation-point={short-label=vpIN_VeCSVR_v_CanSigVehSpd_Value, sw-syscond=1}
              IN_VeDFIR_b_DsblDiagFailSafe_Value: accessed-variable=VeDFIR_b_DsblDiagFailSafe.Value, variation-point={short-label=vpIN_VeDFIR_b_DsblDiagFailSafe_Value, sw-syscond=1}
              IN_VeDFIR_b_IsDiagGlobalConditionsValid_Value: accessed-variable=VeDFIR_b_IsDiagGlobalConditionsValid.Value, variation-point={short-label=vpIN_VeDFIR_b_IsDiagGlobalConditionsValid_Value, sw-syscond=1}
              IN_VeDFIR_b_PostCodeClrDiagDsbl_Value: accessed-variable=VeDFIR_b_PostCodeClrDiagDsbl.Value, variation-point={short-label=vpIN_VeDFIR_b_PostCodeClrDiagDsbl_Value, sw-syscond=1}
              IN_VeDMAB_y_StatusByte_SpdCntrlSw_Value: accessed-variable=VeDMAB_y_StatusByte_SpdCntrlSw.Value, variation-point={short-label=vpIN_VeDMAB_y_StatusByte_SpdCntrlSw_Value, sw-syscond=1}
              IN_VeDMAB_y_StatusByte_SpdCntrlSw1_Value: accessed-variable=VeDMAB_y_StatusByte_SpdCntrlSw1.Value, variation-point={short-label=vpIN_VeDMAB_y_StatusByte_SpdCntrlSw1_Value, sw-syscond=1}
              IN_VeDTRR_P_PtcPdlMaxPwr_Value: accessed-variable=VeDTRR_P_PtcPdlMaxPwr.Value, variation-point={short-label=vpIN_VeDTRR_P_PtcPdlMaxPwr_Value, sw-syscond=1}
              IN_VeDTRR_P_PtcPdlMinPwr_Value: accessed-variable=VeDTRR_P_PtcPdlMinPwr.Value, variation-point={short-label=vpIN_VeDTRR_P_PtcPdlMinPwr_Value, sw-syscond=1}
              IN_VeDTRR_P_PtcPdlPwrReq_Value: accessed-variable=VeDTRR_P_PtcPdlPwrReq.Value, variation-point={short-label=vpIN_VeDTRR_P_PtcPdlPwrReq_Value, sw-syscond=1}
              IN_VeDTRR_b_PtcPdlInChrgVsCC_Value: accessed-variable=VeDTRR_b_PtcPdlInChrgVsCC.Value, variation-point={short-label=vpIN_VeDTRR_b_PtcPdlInChrgVsCC_Value, sw-syscond=1}
              IN_VeGRAR_b_DisableCC_Value: accessed-variable=VeGRAR_b_DisableCC.Value, variation-point={short-label=vpIN_VeGRAR_b_DisableCC_Value, sw-syscond=1}
              IN_VePLTR_Pct_ProxiSpdomtrTol_Value: accessed-variable=VePLTR_Pct_ProxiSpdomtrTol.Value, variation-point={short-label=vpIN_VePLTR_Pct_ProxiSpdomtrTol_Value, sw-syscond=1}
              IN_VePLTR_b_EPBHoldStsFA_Value: accessed-variable=VePLTR_b_EPBHoldStsFA.Value, variation-point={short-label=vpIN_VePLTR_b_EPBHoldStsFA_Value, sw-syscond=1}
              IN_VePLTR_b_HDCEnabledCAN_Value: accessed-variable=VePLTR_b_HDCEnabledCAN.Value, variation-point={short-label=vpIN_VePLTR_b_HDCEnabledCAN_Value, sw-syscond=1}
              IN_VePLTR_b_HDCEnabledCAN_FA_Value: accessed-variable=VePLTR_b_HDCEnabledCAN_FA.Value, variation-point={short-label=vpIN_VePLTR_b_HDCEnabledCAN_FA_Value, sw-syscond=1}
              IN_VePLTR_b_Hill_Des_Stat_Prx_Value: accessed-variable=VePLTR_b_Hill_Des_Stat_Prx.Value, variation-point={short-label=vpIN_VePLTR_b_Hill_Des_Stat_Prx_Value, sw-syscond=1}
              IN_VePLTR_b_ParkBrakeSts_Value: accessed-variable=VePLTR_b_ParkBrakeSts.Value, variation-point={short-label=vpIN_VePLTR_b_ParkBrakeSts_Value, sw-syscond=1}
              IN_VePLTR_b_ProxiCC_Value: accessed-variable=VePLTR_b_ProxiCC.Value, variation-point={short-label=vpIN_VePLTR_b_ProxiCC_Value, sw-syscond=1}
              IN_VePLTR_b_ProxiSpdLimiter_Value: accessed-variable=VePLTR_b_ProxiSpdLimiter.Value, variation-point={short-label=vpIN_VePLTR_b_ProxiSpdLimiter_Value, sw-syscond=1}
              IN_VePLTR_b_SpeedUnit_Value: accessed-variable=VePLTR_b_SpeedUnit.Value, variation-point={short-label=vpIN_VePLTR_b_SpeedUnit_Value, sw-syscond=1}
              IN_VePLTR_e_BSM_AxleTrq_Enbld_Value: accessed-variable=VePLTR_e_BSM_AxleTrq_Enbld.Value, variation-point={short-label=vpIN_VePLTR_e_BSM_AxleTrq_Enbld_Value, sw-syscond=1}
              IN_VePLTR_e_EPBHoldSts_Value: accessed-variable=VePLTR_e_EPBHoldSts.Value, variation-point={short-label=vpIN_VePLTR_e_EPBHoldSts_Value, sw-syscond=1}
              IN_VePLTR_e_ProxiACC_Value: accessed-variable=VePLTR_e_ProxiACC.Value, variation-point={short-label=vpIN_VePLTR_e_ProxiACC_Value, sw-syscond=1}
              IN_VePLTR_e_ProxiIncreasingSpdCnst_Value: accessed-variable=VePLTR_e_ProxiIncreasingSpdCnst.Value, variation-point={short-label=vpIN_VePLTR_e_ProxiIncreasingSpdCnst_Value, sw-syscond=1}
              IN_VePLTR_e_Proxi_CC_Logic_Value: accessed-variable=VePLTR_e_Proxi_CC_Logic.Value, variation-point={short-label=vpIN_VePLTR_e_Proxi_CC_Logic_Value, sw-syscond=1}
              IN_VePLTR_v_HomSpdLim_Value: accessed-variable=VePLTR_v_HomSpdLim.Value, variation-point={short-label=vpIN_VePLTR_v_HomSpdLim_Value, sw-syscond=1}
              IN_VePMDR_e_PMM_PowerMode_Value: accessed-variable=VePMDR_e_PMM_PowerMode.Value, variation-point={short-label=vpIN_VePMDR_e_PMM_PowerMode_Value, sw-syscond=1}
              IN_VeSRAR_b_InhibitCruise_Value: accessed-variable=VeSRAR_b_InhibitCruise.Value, variation-point={short-label=vpIN_VeSRAR_b_InhibitCruise_Value, sw-syscond=1}
              IN_VeTMDR_e_TrrnMd_Value: accessed-variable=VeTMDR_e_TrrnMd.Value, variation-point={short-label=vpIN_VeTMDR_e_TrrnMd_Value, sw-syscond=1}
              IN_VeTRGR_e_VldtdTransRngSt_Value: accessed-variable=VeTRGR_e_VldtdTransRngSt.Value, variation-point={short-label=vpIN_VeTRGR_e_VldtdTransRngSt_Value, sw-syscond=1}
          data-send-points:
            23 x access:
              OUT_VeCCTR_b_CcAccelSts_Value: accessed-variable=VeCCTR_b_CcAccelSts.Value, variation-point={short-label=vpOUT_VeCCTR_b_CcAccelSts_Value, sw-syscond=1}
              OUT_VeCCTR_b_CcDecelSts_Value: accessed-variable=VeCCTR_b_CcDecelSts.Value, variation-point={short-label=vpOUT_VeCCTR_b_CcDecelSts_Value, sw-syscond=1}
              OUT_VeCCTR_b_CcCancelSw_Value: accessed-variable=VeCCTR_b_CcCancelSw.Value, variation-point={short-label=vpOUT_VeCCTR_b_CcCancelSw_Value, sw-syscond=1}
              OUT_VeCCTR_b_CcResumeSw_Value: accessed-variable=VeCCTR_b_CcResumeSw.Value, variation-point={short-label=vpOUT_VeCCTR_b_CcResumeSw_Value, sw-syscond=1}
              OUT_VeCCTR_b_Lv1CrusSwStuckFailed_Value: accessed-variable=VeCCTR_b_Lv1CrusSwStuckFailed.Value, variation-point={short-label=vpOUT_VeCCTR_b_Lv1CrusSwStuckFailed_Value, sw-syscond=1}
              OUT_VeCCTR_b_Lv1CrusOffReq_Value: accessed-variable=VeCCTR_b_Lv1CrusOffReq.Value, variation-point={short-label=vpOUT_VeCCTR_b_Lv1CrusOffReq_Value, sw-syscond=1}
              OUT_VeCCTR_e_Lv1CrusCanState_Value: accessed-variable=VeCCTR_e_Lv1CrusCanState.Value, variation-point={short-label=vpOUT_VeCCTR_e_Lv1CrusCanState_Value, sw-syscond=1}
              OUT_VeCCTR_b_CcEngaged_Value: accessed-variable=VeCCTR_b_CcEngaged.Value, variation-point={short-label=vpOUT_VeCCTR_b_CcEngaged_Value, sw-syscond=1}
              OUT_VeCCTR_b_CcLampSts_Value: accessed-variable=VeCCTR_b_CcLampSts.Value, variation-point={short-label=vpOUT_VeCCTR_b_CcLampSts_Value, sw-syscond=1}
              OUT_VeCCTR_v_CcSetSpd_Value: accessed-variable=VeCCTR_v_CcSetSpd.Value, variation-point={short-label=vpOUT_VeCCTR_v_CcSetSpd_Value, sw-syscond=1}
              OUT_VeCCTR_v_CcCntrlSpd_Cluster_KPH_Value: accessed-variable=VeCCTR_v_CcCntrlSpd_Cluster_KPH.Value, variation-point={short-label=vpOUT_VeCCTR_v_CcCntrlSpd_Cluster_KPH_Value, sw-syscond=1}
              OUT_VeCCTR_v_CcCntrlSpd_Cluster_MPH_Value: accessed-variable=VeCCTR_v_CcCntrlSpd_Cluster_MPH.Value, variation-point={short-label=vpOUT_VeCCTR_v_CcCntrlSpd_Cluster_MPH_Value, sw-syscond=1}
              OUT_VeCCTR_b_CcEnabled_Value: accessed-variable=VeCCTR_b_CcEnabled.Value, variation-point={short-label=vpOUT_VeCCTR_b_CcEnabled_Value, sw-syscond=1}
              OUT_VeCCTR_e_ECMWARN_Value: accessed-variable=VeCCTR_e_ECMWARN.Value, variation-point={short-label=vpOUT_VeCCTR_e_ECMWARN_Value, sw-syscond=1}
              OUT_VeCCTR_v_CcVehSpd_Value: accessed-variable=VeCCTR_v_CcVehSpd.Value, variation-point={short-label=vpOUT_VeCCTR_v_CcVehSpd_Value, sw-syscond=1}
              OUT_VeCCTR_b_CcInhEngage_Value: accessed-variable=VeCCTR_b_CcInhEngage.Value, variation-point={short-label=vpOUT_VeCCTR_b_CcInhEngage_Value, sw-syscond=1}
              OUT_VeCCTR_v_CcCntrlSpd_Value: accessed-variable=VeCCTR_v_CcCntrlSpd.Value, variation-point={short-label=vpOUT_VeCCTR_v_CcCntrlSpd_Value, sw-syscond=1}
              OUT_VeCCTR_P_CcPIDTerm_Value: accessed-variable=VeCCTR_P_CcPIDTerm.Value, variation-point={short-label=vpOUT_VeCCTR_P_CcPIDTerm_Value, sw-syscond=1}
              OUT_VeCCTR_P_CcDesiredPwr_Value: accessed-variable=VeCCTR_P_CcDesiredPwr.Value, variation-point={short-label=vpOUT_VeCCTR_P_CcDesiredPwr_Value, sw-syscond=1}
              OUT_VeCCTR_e_FaultSts_SpdCntrlSw_Value: accessed-variable=VeCCTR_e_FaultSts_SpdCntrlSw.Value
              OUT_VeCCTR_b_ACCTrqEnabled_BSM_Value: accessed-variable=VeCCTR_b_ACCTrqEnabled_BSM.Value, variation-point={short-label=vpOUT_VeCCTR_b_ACCTrqEnabled_BSM_Value, sw-syscond=1}
              OUT_VeCCTR_b_ACCTrqEnabled_BSMFA_Value: accessed-variable=VeCCTR_b_ACCTrqEnabled_BSMFA.Value, variation-point={short-label=vpOUT_VeCCTR_b_ACCTrqEnabled_BSMFA_Value, sw-syscond=1}
              OUT_VeCCTR_e_FaultSts_SpdCntrlSw1_Value: accessed-variable=VeCCTR_e_FaultSts_SpdCntrlSw1.Value
          parameter access CALPRM_KeASLR_b_ASLInstantActivationEnable_KeASLR_b_ASLInstantActivationEnable: accessed-parameter=KeASLR_b_ASLInstantActivationEnable.KeASLR_b_ASLInstantActivationEnable, variation-point={short-label=vpCALPRM_KeASLR_b_ASLInstantActivationEnable_KeASLR_b_ASLInstantActivationEnable, sw-syscond=1}
          read-local-variables:
            16 x access:
              RV_ACC_TrqEnabled_BSMFA_IRV: accessed-variable=ACC_TrqEnabled_BSMFA_IRV, variation-point={short-label=vpRV_ACC_TrqEnabled_BSMFA_IRV, sw-syscond=1}
              RV_ACC_TrqEnabled_BSM_IRV: accessed-variable=ACC_TrqEnabled_BSM_IRV, variation-point={short-label=vpRV_ACC_TrqEnabled_BSM_IRV, sw-syscond=1}
              RV_CC_AccelStsFA_write_IRV: accessed-variable=CC_AccelStsFA_write_IRV, variation-point={short-label=vpRV_CC_AccelStsFA_write_IRV, sw-syscond=1}
              RV_CC_Accel_Sts_write_IRV: accessed-variable=CC_Accel_Sts_write_IRV, variation-point={short-label=vpRV_CC_Accel_Sts_write_IRV, sw-syscond=1}
              RV_CC_CancelSwtchFA_write_IRV: accessed-variable=CC_CancelSwtchFA_write_IRV, variation-point={short-label=vpRV_CC_CancelSwtchFA_write_IRV, sw-syscond=1}
              RV_CC_Cancel_Swtch_write_IRV: accessed-variable=CC_Cancel_Swtch_write_IRV, variation-point={short-label=vpRV_CC_Cancel_Swtch_write_IRV, sw-syscond=1}
              RV_CC_CoastDecelStsFA_write_IRV: accessed-variable=CC_CoastDecelStsFA_write_IRV, variation-point={short-label=vpRV_CC_CoastDecelStsFA_write_IRV, sw-syscond=1}
              RV_CC_CoastDecelSts_write_IRV: accessed-variable=CC_CoastDecelSts_write_IRV, variation-point={short-label=vpRV_CC_CoastDecelSts_write_IRV, sw-syscond=1}
              RV_CC_FailStsFA_write_IRV: accessed-variable=CC_FailStsFA_write_IRV, variation-point={short-label=vpRV_CC_FailStsFA_write_IRV, sw-syscond=1}
              RV_CC_FailSts_write_IRV: accessed-variable=CC_FailSts_write_IRV, variation-point={short-label=vpRV_CC_FailSts_write_IRV, sw-syscond=1}
              RV_CC_OnOffStsFA_write_IRV: accessed-variable=CC_OnOffStsFA_write_IRV, variation-point={short-label=vpRV_CC_OnOffStsFA_write_IRV, sw-syscond=1}
              RV_CC_OnOff_Sts_write_IRV: accessed-variable=CC_OnOff_Sts_write_IRV, variation-point={short-label=vpRV_CC_OnOff_Sts_write_IRV, sw-syscond=1}
              RV_CC_ResumeSwtchFA_write_IRV: accessed-variable=CC_ResumeSwtchFA_write_IRV, variation-point={short-label=vpRV_CC_ResumeSwtchFA_write_IRV, sw-syscond=1}
              RV_CC_ResumeSwtch_write_IRV: accessed-variable=CC_ResumeSwtch_write_IRV, variation-point={short-label=vpRV_CC_ResumeSwtch_write_IRV, sw-syscond=1}
              RV_CC_SetSwtchFA_write_IRV: accessed-variable=CC_SetSwtchFA_write_IRV, variation-point={short-label=vpRV_CC_SetSwtchFA_write_IRV, sw-syscond=1}
              RV_CC_SetSwtch_write_IRV: accessed-variable=CC_SetSwtch_write_IRV, variation-point={short-label=vpRV_CC_SetSwtch_write_IRV, sw-syscond=1}
        CCTR_PwrOff
          data-send-points:
            access OUT_NeCCTR_Cnt_SpdCntrlSw1_MFOP_NeCCTR_Cnt_SpdCntrlSw1_MFOP: accessed-variable=NeCCTR_Cnt_SpdCntrlSw1_MFOP.NeCCTR_Cnt_SpdCntrlSw1_MFOP
        FsftCCTR_M_ACCTrq_BSM: variation-point={short-label=vpFsftCCTR_M_ACCTrq_BSM, sw-syscond=1}
          data-send-points:
            access OUT_VeCCTR_b_ACCTrq_BSMFA_Value: accessed-variable=VeCCTR_b_ACCTrq_BSMFA.Value
        FsftCCTR_b_ACCTrqEnabled_BSM: variation-point={short-label=vpFsftCCTR_b_ACCTrqEnabled_BSM, sw-syscond=1}
          written-local-variables:
            access WV_ACC_TrqEnabled_BSMFA_IRV: accessed-variable=ACC_TrqEnabled_BSMFA_IRV, variation-point={short-label=vpWV_ACC_TrqEnabled_BSMFA_IRV, sw-syscond=1}
        FsftCCTR_b_CcAccelSts: variation-point={short-label=vpFsftCCTR_b_CcAccelSts, sw-syscond=1}
          data-send-points:
            access OUT_VeCCTR_b_CcAccelStsFA_Value: accessed-variable=VeCCTR_b_CcAccelStsFA.Value
          written-local-variables:
            access WV_CC_AccelStsFA_write_IRV: accessed-variable=CC_AccelStsFA_write_IRV, variation-point={short-label=vpWV_CC_AccelStsFA_write_IRV, sw-syscond=1}
        FsftCCTR_b_CcCancelSw: variation-point={short-label=vpFsftCCTR_b_CcCancelSw, sw-syscond=1}
          data-send-points:
            access OUT_VeCCTR_b_CcCancelSwFA_Value: accessed-variable=VeCCTR_b_CcCancelSwFA.Value
          written-local-variables:
            access WV_CC_CancelSwtchFA_write_IRV: accessed-variable=CC_CancelSwtchFA_write_IRV, variation-point={short-label=vpWV_CC_CancelSwtchFA_write_IRV, sw-syscond=1}
        FsftCCTR_b_CcDecelSts: variation-point={short-label=vpFsftCCTR_b_CcDecelSts, sw-syscond=1}
          data-send-points:
            access OUT_VeCCTR_b_CcDecelStsFA_Value: accessed-variable=VeCCTR_b_CcDecelStsFA.Value
          written-local-variables:
            access WV_CC_CoastDecelStsFA_write_IRV: accessed-variable=CC_CoastDecelStsFA_write_IRV, variation-point={short-label=vpWV_CC_CoastDecelStsFA_write_IRV, sw-syscond=1}
        FsftCCTR_b_CcFailSts: variation-point={short-label=vpFsftCCTR_b_CcFailSts, sw-syscond=1}
          data-send-points:
            access OUT_VeCCTR_b_CcFailStsFA_Value: accessed-variable=VeCCTR_b_CcFailStsFA.Value
          written-local-variables:
            access WV_CC_FailStsFA_write_IRV: accessed-variable=CC_FailStsFA_write_IRV, variation-point={short-label=vpWV_CC_FailStsFA_write_IRV, sw-syscond=1}
        FsftCCTR_b_CcOnOffSts: variation-point={short-label=vpFsftCCTR_b_CcOnOffSts, sw-syscond=1}
          data-send-points:
            access OUT_VeCCTR_b_CcOnOffStsFA_Value: accessed-variable=VeCCTR_b_CcOnOffStsFA.Value
          written-local-variables:
            access WV_CC_OnOffStsFA_write_IRV: accessed-variable=CC_OnOffStsFA_write_IRV, variation-point={short-label=vpWV_CC_OnOffStsFA_write_IRV, sw-syscond=1}
        FsftCCTR_b_CcResumeSw: variation-point={short-label=vpFsftCCTR_b_CcResumeSw, sw-syscond=1}
          data-send-points:
            access OUT_VeCCTR_b_CcResumeSwFA_Value: accessed-variable=VeCCTR_b_CcResumeSwFA.Value
          written-local-variables:
            access WV_CC_ResumeSwtchFA_write_IRV: accessed-variable=CC_ResumeSwtchFA_write_IRV, variation-point={short-label=vpWV_CC_ResumeSwtchFA_write_IRV, sw-syscond=1}
        FsftCCTR_b_CcSetSw: variation-point={short-label=vpFsftCCTR_b_CcSetSw, sw-syscond=1}
          written-local-variables:
            access WV_CC_SetSwtchFA_write_IRV: accessed-variable=CC_SetSwtchFA_write_IRV, variation-point={short-label=vpWV_CC_SetSwtchFA_write_IRV, sw-syscond=1}
        PokeCCTR_M_ACCTrq_BSM: variation-point={short-label=vpPokeCCTR_M_ACCTrq_BSM, sw-syscond=1}
          data-send-points:
            access OUT_VeCCTR_M_ACCTrq_BSM_Value: accessed-variable=VeCCTR_M_ACCTrq_BSM.Value
            access OUT_VeCCTR_b_ACCTrq_BSMFA_Value: accessed-variable=VeCCTR_b_ACCTrq_BSMFA.Value
        PokeCCTR_b_ACCEngaged: variation-point={short-label=vpPokeCCTR_b_ACCEngaged, sw-syscond=1}
        PokeCCTR_b_ACCTrqEnabled_BSM: variation-point={short-label=vpPokeCCTR_b_ACCTrqEnabled_BSM, sw-syscond=1}
          written-local-variables:
            access WV_ACC_TrqEnabled_BSMFA_IRV: accessed-variable=ACC_TrqEnabled_BSMFA_IRV, variation-point={short-label=vpWV_ACC_TrqEnabled_BSMFA_IRV, sw-syscond=1}
            access WV_ACC_TrqEnabled_BSM_IRV: accessed-variable=ACC_TrqEnabled_BSM_IRV, variation-point={short-label=vpWV_ACC_TrqEnabled_BSM_IRV, sw-syscond=1}
        PokeCCTR_b_CcAccelSts: variation-point={short-label=vpPokeCCTR_b_CcAccelSts, sw-syscond=1}
          data-send-points:
            access OUT_VeCCTR_b_CcAccelStsFA_Value: accessed-variable=VeCCTR_b_CcAccelStsFA.Value
          written-local-variables:
            access WV_CC_AccelStsFA_write_IRV: accessed-variable=CC_AccelStsFA_write_IRV, variation-point={short-label=vpWV_CC_AccelStsFA_write_IRV, sw-syscond=1}
            access WV_CC_Accel_Sts_write_IRV: accessed-variable=CC_Accel_Sts_write_IRV, variation-point={short-label=vpWV_CC_Accel_Sts_write_IRV, sw-syscond=1}
        PokeCCTR_b_CcCancelSw: variation-point={short-label=vpPokeCCTR_b_CcCancelSw, sw-syscond=1}
          data-send-points:
            access OUT_VeCCTR_b_CcCancelSwFA_Value: accessed-variable=VeCCTR_b_CcCancelSwFA.Value
          written-local-variables:
            access WV_CC_CancelSwtchFA_write_IRV: accessed-variable=CC_CancelSwtchFA_write_IRV, variation-point={short-label=vpWV_CC_CancelSwtchFA_write_IRV, sw-syscond=1}
            access WV_CC_Cancel_Swtch_write_IRV: accessed-variable=CC_Cancel_Swtch_write_IRV, variation-point={short-label=vpWV_CC_Cancel_Swtch_write_IRV, sw-syscond=1}
        PokeCCTR_b_CcDecelSts: variation-point={short-label=vpPokeCCTR_b_CcDecelSts, sw-syscond=1}
          data-send-points:
            access OUT_VeCCTR_b_CcDecelStsFA_Value: accessed-variable=VeCCTR_b_CcDecelStsFA.Value
          written-local-variables:
            access WV_CC_CoastDecelStsFA_write_IRV: accessed-variable=CC_CoastDecelStsFA_write_IRV, variation-point={short-label=vpWV_CC_CoastDecelStsFA_write_IRV, sw-syscond=1}
            access WV_CC_CoastDecelSts_write_IRV: accessed-variable=CC_CoastDecelSts_write_IRV, variation-point={short-label=vpWV_CC_CoastDecelSts_write_IRV, sw-syscond=1}
        PokeCCTR_b_CcFailSts: variation-point={short-label=vpPokeCCTR_b_CcFailSts, sw-syscond=1}
          data-send-points:
            access OUT_VeCCTR_b_CcFailSts_Value: accessed-variable=VeCCTR_b_CcFailSts.Value
            access OUT_VeCCTR_b_CcFailStsFA_Value: accessed-variable=VeCCTR_b_CcFailStsFA.Value
          written-local-variables:
            access WV_CC_FailStsFA_write_IRV: accessed-variable=CC_FailStsFA_write_IRV, variation-point={short-label=vpWV_CC_FailStsFA_write_IRV, sw-syscond=1}
            access WV_CC_FailSts_write_IRV: accessed-variable=CC_FailSts_write_IRV, variation-point={short-label=vpWV_CC_FailSts_write_IRV, sw-syscond=1}
        PokeCCTR_b_CcOnOffSts: variation-point={short-label=vpPokeCCTR_b_CcOnOffSts, sw-syscond=1}
          data-send-points:
            access OUT_VeCCTR_b_CcOnOffSts_Value: accessed-variable=VeCCTR_b_CcOnOffSts.Value
            access OUT_VeCCTR_b_CcOnOffStsFA_Value: accessed-variable=VeCCTR_b_CcOnOffStsFA.Value
          written-local-variables:
            access WV_CC_OnOffStsFA_write_IRV: accessed-variable=CC_OnOffStsFA_write_IRV, variation-point={short-label=vpWV_CC_OnOffStsFA_write_IRV, sw-syscond=1}
            access WV_CC_OnOff_Sts_write_IRV: accessed-variable=CC_OnOff_Sts_write_IRV, variation-point={short-label=vpWV_CC_OnOff_Sts_write_IRV, sw-syscond=1}
        PokeCCTR_b_CcResumeSw: variation-point={short-label=vpPokeCCTR_b_CcResumeSw, sw-syscond=1}
          data-send-points:
            access OUT_VeCCTR_b_CcResumeSwFA_Value: accessed-variable=VeCCTR_b_CcResumeSwFA.Value
          written-local-variables:
            access WV_CC_ResumeSwtchFA_write_IRV: accessed-variable=CC_ResumeSwtchFA_write_IRV, variation-point={short-label=vpWV_CC_ResumeSwtchFA_write_IRV, sw-syscond=1}
            access WV_CC_ResumeSwtch_write_IRV: accessed-variable=CC_ResumeSwtch_write_IRV, variation-point={short-label=vpWV_CC_ResumeSwtch_write_IRV, sw-syscond=1}
        PokeCCTR_b_CcSetSw: variation-point={short-label=vpPokeCCTR_b_CcSetSw, sw-syscond=1}
          written-local-variables:
            access WV_CC_SetSwtch_write_IRV: accessed-variable=CC_SetSwtch_write_IRV, variation-point={short-label=vpWV_CC_SetSwtch_write_IRV, sw-syscond=1}
      variation point proxy Variant_CCTR_2: category=CONDITION, condition-access=0
      variation point proxy Variant_CCTR_3: category=CONDITION, condition-access=1
      variation point proxy Variant_CCTR_4: category=CONDITION, condition-access=0
